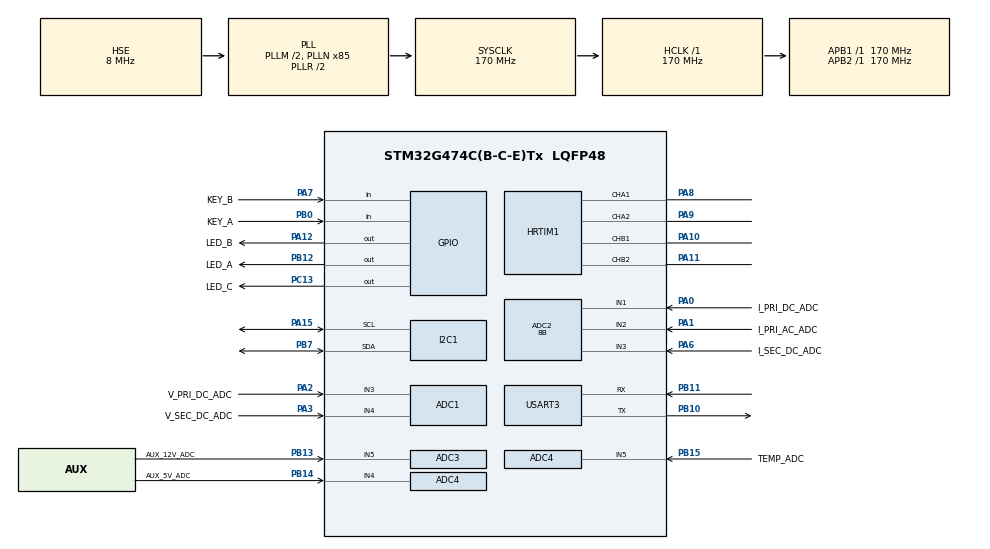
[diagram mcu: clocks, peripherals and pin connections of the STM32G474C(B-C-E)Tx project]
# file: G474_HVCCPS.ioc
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ADC1.Channel-0\#ChannelRegularConversion=ADC_CHANNEL_4
ADC1.Channel-1\#ChannelRegularConversion=ADC_CHANNEL_3
ADC1.DMAContinuousRequests=ENABLE
ADC1.EOCSelection=ADC_EOC_SEQ_CONV
ADC1.EnableInjectedConversion=DISABLE
ADC1.ExternalTrigConv=ADC_EXTERNALTRIG_HRTIM_TRG1
ADC1.NbrOfConversion=2
ADC1.NbrOfConversionFlag=1
ADC1.OffsetNumber-0\#ChannelRegularConversion=ADC_OFFSET_NONE
ADC1.OffsetNumber-1\#ChannelRegularConversion=ADC_OFFSET_NONE
ADC1.Overrun=ADC_OVR_DATA_OVERWRITTEN
ADC1.OversamplingMode=DISABLE
ADC1.Rank-0\#ChannelRegularConversion=1
ADC1.Rank-1\#ChannelRegularConversion=2
ADC1.Rank1_Channel=ADC_CHANNEL_3
ADC1.SamplingTime-0\#ChannelRegularConversion=ADC_SAMPLETIME_2CYCLES_5
ADC1.SamplingTime-1\#ChannelRegularConversion=ADC_SAMPLETIME_2CYCLES_5
ADC1.master=1
ADC2.Channel-12\#ChannelRegularConversion=ADC_CHANNEL_2
ADC2.Channel-14\#ChannelRegularConversion=ADC_CHANNEL_3
ADC2.Channel-15\#ChannelRegularConversion=ADC_CHANNEL_1
ADC2.ContinuousConvMode=DISABLE
ADC2.DMAContinuousRequests=ENABLE
ADC2.EOCSelection=ADC_EOC_SEQ_CONV
ADC2.EnableInjectedConversion=DISABLE
ADC2.EnableRegularConversion=ENABLE
ADC2.ExternalTrigConv=ADC_EXTERNALTRIG_HRTIM_TRG1
ADC2.NbrOfConversion=3
ADC2.NbrOfConversionFlag=1
ADC2.OffsetNumber-12\#ChannelRegularConversion=ADC_OFFSET_NONE
ADC2.OffsetNumber-14\#ChannelRegularConversion=ADC_OFFSET_NONE
ADC2.OffsetNumber-15\#ChannelRegularConversion=ADC_OFFSET_NONE
ADC2.Overrun=ADC_OVR_DATA_OVERWRITTEN
ADC2.Rank-12\#ChannelRegularConversion=1
ADC2.Rank-14\#ChannelRegularConversion=2
ADC2.Rank-15\#ChannelRegularConversion=3
ADC2.Resolution=ADC_RESOLUTION_8B
ADC2.SamplingTime-12\#ChannelRegularConversion=ADC_SAMPLETIME_2CYCLES_5
ADC2.SamplingTime-14\#ChannelRegularConversion=ADC_SAMPLETIME_2CYCLES_5
ADC2.SamplingTime-15\#ChannelRegularConversion=ADC_SAMPLETIME_2CYCLES_5
ADC3.Channel-1\#ChannelRegularConversion=ADC_CHANNEL_5
ADC3.ClockPrescaler=ADC_CLOCK_SYNC_PCLK_DIV4
ADC3.ContinuousConvMode=DISABLE
ADC3.DMAContinuousRequests=ENABLE
ADC3.EOCSelection=ADC_EOC_SEQ_CONV
ADC3.ExternalTrigConv=ADC_EXTERNALTRIG_HRTIM_TRG3
ADC3.NbrOfConversion=1
ADC3.NbrOfConversionFlag=1
ADC3.OffsetNumber-1\#ChannelRegularConversion=ADC_OFFSET_NONE
ADC3.Overrun=ADC_OVR_DATA_OVERWRITTEN
ADC3.OversamplingMode=DISABLE
ADC3.Rank-1\#ChannelRegularConversion=1
ADC3.SamplingTime-1\#ChannelRegularConversion=ADC_SAMPLETIME_6CYCLES_5
ADC3.master=1
ADC4.Channel-0\#ChannelRegularConversion=ADC_CHANNEL_4
ADC4.Channel-2\#ChannelRegularConversion=ADC_CHANNEL_5
ADC4.ContinuousConvMode=DISABLE
ADC4.DMAContinuousRequests=ENABLE
ADC4.EOCSelection=ADC_EOC_SEQ_CONV
ADC4.ExternalTrigConv=ADC_EXTERNALTRIG_HRTIM_TRG3
ADC4.NbrOfConversion=2
ADC4.NbrOfConversionFlag=1
ADC4.OffsetNumber-0\#ChannelRegularConversion=ADC_OFFSET_NONE
ADC4.OffsetNumber-2\#ChannelRegularConversion=ADC_OFFSET_NONE
ADC4.Overrun=ADC_OVR_DATA_OVERWRITTEN
ADC4.OversamplingMode=DISABLE
ADC4.Rank-0\#ChannelRegularConversion=1
ADC4.Rank-2\#ChannelRegularConversion=2
ADC4.SamplingTime-0\#ChannelRegularConversion=ADC_SAMPLETIME_6CYCLES_5
ADC4.SamplingTime-2\#ChannelRegularConversion=ADC_SAMPLETIME_6CYCLES_5
ADC5.Channel-0\#ChannelRegularConversion=ADC_CHANNEL_TEMPSENSOR_ADC5
ADC5.Channel-1\#ChannelRegularConversion=ADC_CHANNEL_VREFINT
ADC5.ContinuousConvMode=DISABLE
ADC5.DMAContinuousRequests=ENABLE
ADC5.EOCSelection=ADC_EOC_SEQ_CONV
ADC5.ExternalTrigConv=ADC_EXTERNALTRIG_HRTIM_TRG2
ADC5.NbrOfConversion=2
ADC5.NbrOfConversionFlag=1
ADC5.OffsetNumber-0\#ChannelRegularConversion=ADC_OFFSET_NONE
ADC5.OffsetNumber-1\#ChannelRegularConversion=ADC_OFFSET_NONE
ADC5.Overrun=ADC_OVR_DATA_OVERWRITTEN
ADC5.OversamplingMode=DISABLE
ADC5.Rank-0\#ChannelRegularConversion=1
ADC5.Rank-1\#ChannelRegularConversion=2
ADC5.SamplingTime-0\#ChannelRegularConversion=ADC_SAMPLETIME_247CYCLES_5
ADC5.SamplingTime-1\#ChannelRegularConversion=ADC_SAMPLETIME_247CYCLES_5
COMP1.TriggerMode=COMP_TRIGGERMODE_EVENT_RISING
DAC1.DAC_SampleAndHold-DAC_OUT1_Int=DAC_SAMPLEANDHOLD_DISABLE
Dma.ADC1.5.Direction=DMA_PERIPH_TO_MEMORY
Dma.ADC1.5.EventEnable=DISABLE
Dma.ADC1.5.Instance=DMA1_Channel1
Dma.ADC1.5.MemDataAlignment=DMA_MDATAALIGN_HALFWORD
Dma.ADC1.5.MemInc=DMA_MINC_ENABLE
Dma.ADC1.5.Mode=DMA_CIRCULAR
Dma.ADC1.5.PeriphDataAlignment=DMA_PDATAALIGN_HALFWORD
Dma.ADC1.5.PeriphInc=DMA_PINC_DISABLE
Dma.ADC1.5.Polarity=HAL_DMAMUX_REQ_GEN_RISING
Dma.ADC1.5.Priority=DMA_PRIORITY_HIGH
Dma.ADC1.5.RequestNumber=1
Dma.ADC1.5.SignalID=NONE
Dma.ADC1.5.SyncEnable=DISABLE
Dma.ADC1.5.SyncPolarity=HAL_DMAMUX_SYNC_NO_EVENT
Dma.ADC1.5.SyncRequestNumber=1
Dma.ADC1.5.SyncSignalID=NONE
Dma.ADC2.6.Direction=DMA_PERIPH_TO_MEMORY
Dma.ADC2.6.EventEnable=DISABLE
Dma.ADC2.6.Instance=DMA1_Channel2
Dma.ADC2.6.MemDataAlignment=DMA_MDATAALIGN_HALFWORD
Dma.ADC2.6.MemInc=DMA_MINC_ENABLE
Dma.ADC2.6.Mode=DMA_CIRCULAR
Dma.ADC2.6.PeriphDataAlignment=DMA_PDATAALIGN_HALFWORD
Dma.ADC2.6.PeriphInc=DMA_PINC_DISABLE
Dma.ADC2.6.Polarity=HAL_DMAMUX_REQ_GEN_RISING
Dma.ADC2.6.Priority=DMA_PRIORITY_HIGH
Dma.ADC2.6.RequestNumber=1
Dma.ADC2.6.SignalID=NONE
Dma.ADC2.6.SyncEnable=DISABLE
Dma.ADC2.6.SyncPolarity=HAL_DMAMUX_SYNC_NO_EVENT
Dma.ADC2.6.SyncRequestNumber=1
Dma.ADC2.6.SyncSignalID=NONE
Dma.ADC3.2.Direction=DMA_PERIPH_TO_MEMORY
Dma.ADC3.2.EventEnable=DISABLE
Dma.ADC3.2.Instance=DMA2_Channel1
Dma.ADC3.2.MemDataAlignment=DMA_MDATAALIGN_HALFWORD
Dma.ADC3.2.MemInc=DMA_MINC_ENABLE
Dma.ADC3.2.Mode=DMA_CIRCULAR
Dma.ADC3.2.PeriphDataAlignment=DMA_PDATAALIGN_HALFWORD
Dma.ADC3.2.PeriphInc=DMA_PINC_DISABLE
Dma.ADC3.2.Polarity=HAL_DMAMUX_REQ_GEN_RISING
Dma.ADC3.2.Priority=DMA_PRIORITY_HIGH
Dma.ADC3.2.RequestNumber=1
Dma.ADC3.2.SignalID=NONE
Dma.ADC3.2.SyncEnable=DISABLE
Dma.ADC3.2.SyncPolarity=HAL_DMAMUX_SYNC_NO_EVENT
Dma.ADC3.2.SyncRequestNumber=1
Dma.ADC3.2.SyncSignalID=NONE
Dma.ADC4.3.Direction=DMA_PERIPH_TO_MEMORY
Dma.ADC4.3.EventEnable=DISABLE
Dma.ADC4.3.Instance=DMA2_Channel2
Dma.ADC4.3.MemDataAlignment=DMA_MDATAALIGN_HALFWORD
Dma.ADC4.3.MemInc=DMA_MINC_ENABLE
Dma.ADC4.3.Mode=DMA_CIRCULAR
Dma.ADC4.3.PeriphDataAlignment=DMA_PDATAALIGN_HALFWORD
Dma.ADC4.3.PeriphInc=DMA_PINC_DISABLE
Dma.ADC4.3.Polarity=HAL_DMAMUX_REQ_GEN_RISING
Dma.ADC4.3.Priority=DMA_PRIORITY_HIGH
Dma.ADC4.3.RequestNumber=1
Dma.ADC4.3.SignalID=NONE
Dma.ADC4.3.SyncEnable=DISABLE
Dma.ADC4.3.SyncPolarity=HAL_DMAMUX_SYNC_NO_EVENT
Dma.ADC4.3.SyncRequestNumber=1
Dma.ADC4.3.SyncSignalID=NONE
Dma.ADC5.4.Direction=DMA_PERIPH_TO_MEMORY
Dma.ADC5.4.EventEnable=DISABLE
Dma.ADC5.4.Instance=DMA2_Channel3
Dma.ADC5.4.MemDataAlignment=DMA_MDATAALIGN_HALFWORD
Dma.ADC5.4.MemInc=DMA_MINC_ENABLE
Dma.ADC5.4.Mode=DMA_CIRCULAR
Dma.ADC5.4.PeriphDataAlignment=DMA_PDATAALIGN_HALFWORD
Dma.ADC5.4.PeriphInc=DMA_PINC_DISABLE
Dma.ADC5.4.Polarity=HAL_DMAMUX_REQ_GEN_RISING
Dma.ADC5.4.Priority=DMA_PRIORITY_HIGH
Dma.ADC5.4.RequestNumber=1
Dma.ADC5.4.SignalID=NONE
Dma.ADC5.4.SyncEnable=DISABLE
Dma.ADC5.4.SyncPolarity=HAL_DMAMUX_SYNC_NO_EVENT
Dma.ADC5.4.SyncRequestNumber=1
Dma.ADC5.4.SyncSignalID=NONE
Dma.I2C1_RX.7.Direction=DMA_PERIPH_TO_MEMORY
Dma.I2C1_RX.7.EventEnable=DISABLE
Dma.I2C1_RX.7.Instance=DMA2_Channel6
Dma.I2C1_RX.7.MemDataAlignment=DMA_MDATAALIGN_BYTE
Dma.I2C1_RX.7.MemInc=DMA_MINC_ENABLE
Dma.I2C1_RX.7.Mode=DMA_NORMAL
Dma.I2C1_RX.7.PeriphDataAlignment=DMA_PDATAALIGN_BYTE
Dma.I2C1_RX.7.PeriphInc=DMA_PINC_DISABLE
Dma.I2C1_RX.7.Polarity=HAL_DMAMUX_REQ_GEN_RISING
Dma.I2C1_RX.7.Priority=DMA_PRIORITY_MEDIUM
Dma.I2C1_RX.7.RequestNumber=1
Dma.I2C1_RX.7.SignalID=NONE
Dma.I2C1_RX.7.SyncEnable=DISABLE
Dma.I2C1_RX.7.SyncPolarity=HAL_DMAMUX_SYNC_NO_EVENT
Dma.I2C1_RX.7.SyncRequestNumber=1
Dma.I2C1_RX.7.SyncSignalID=NONE
Dma.I2C1_TX.8.Direction=DMA_MEMORY_TO_PERIPH
Dma.I2C1_TX.8.EventEnable=DISABLE
Dma.I2C1_TX.8.Instance=DMA2_Channel7
Dma.I2C1_TX.8.MemDataAlignment=DMA_MDATAALIGN_BYTE
Dma.I2C1_TX.8.MemInc=DMA_MINC_ENABLE
Dma.I2C1_TX.8.Mode=DMA_NORMAL
Dma.I2C1_TX.8.PeriphDataAlignment=DMA_PDATAALIGN_BYTE
Dma.I2C1_TX.8.PeriphInc=DMA_PINC_DISABLE
Dma.I2C1_TX.8.Polarity=HAL_DMAMUX_REQ_GEN_RISING
Dma.I2C1_TX.8.Priority=DMA_PRIORITY_MEDIUM
Dma.I2C1_TX.8.RequestNumber=1
Dma.I2C1_TX.8.SignalID=NONE
Dma.I2C1_TX.8.SyncEnable=DISABLE
Dma.I2C1_TX.8.SyncPolarity=HAL_DMAMUX_SYNC_NO_EVENT
Dma.I2C1_TX.8.SyncRequestNumber=1
Dma.I2C1_TX.8.SyncSignalID=NONE
Dma.Request0=USART3_RX
Dma.Request1=USART3_TX
Dma.Request2=ADC3
Dma.Request3=ADC4
Dma.Request4=ADC5
Dma.Request5=ADC1
Dma.Request6=ADC2
Dma.Request7=I2C1_RX
Dma.Request8=I2C1_TX
Dma.USART3_RX.0.Direction=DMA_PERIPH_TO_MEMORY
Dma.USART3_RX.0.EventEnable=DISABLE
Dma.USART3_RX.0.Instance=DMA2_Channel5
Dma.USART3_RX.0.MemDataAlignment=DMA_MDATAALIGN_BYTE
Dma.USART3_RX.0.MemInc=DMA_MINC_ENABLE
Dma.USART3_RX.0.Mode=DMA_NORMAL
Dma.USART3_RX.0.PeriphDataAlignment=DMA_PDATAALIGN_BYTE
Dma.USART3_RX.0.PeriphInc=DMA_PINC_DISABLE
Dma.USART3_RX.0.Polarity=HAL_DMAMUX_REQ_GEN_RISING
Dma.USART3_RX.0.Priority=DMA_PRIORITY_MEDIUM
Dma.USART3_RX.0.RequestNumber=1
Dma.USART3_RX.0.SignalID=NONE
Dma.USART3_RX.0.SyncEnable=DISABLE
Dma.USART3_RX.0.SyncPolarity=HAL_DMAMUX_SYNC_NO_EVENT
Dma.USART3_RX.0.SyncRequestNumber=1
Dma.USART3_RX.0.SyncSignalID=NONE
Dma.USART3_TX.1.Direction=DMA_MEMORY_TO_PERIPH
Dma.USART3_TX.1.EventEnable=DISABLE
Dma.USART3_TX.1.Instance=DMA2_Channel4
Dma.USART3_TX.1.MemDataAlignment=DMA_MDATAALIGN_BYTE
Dma.USART3_TX.1.MemInc=DMA_MINC_ENABLE
Dma.USART3_TX.1.Mode=DMA_NORMAL
Dma.USART3_TX.1.PeriphDataAlignment=DMA_PDATAALIGN_BYTE
Dma.USART3_TX.1.PeriphInc=DMA_PINC_DISABLE
Dma.USART3_TX.1.Polarity=HAL_DMAMUX_REQ_GEN_RISING
Dma.USART3_TX.1.Priority=DMA_PRIORITY_MEDIUM
Dma.USART3_TX.1.RequestNumber=1
Dma.USART3_TX.1.SignalID=NONE
Dma.USART3_TX.1.SyncEnable=DISABLE
Dma.USART3_TX.1.SyncPolarity=HAL_DMAMUX_SYNC_NO_EVENT
Dma.USART3_TX.1.SyncRequestNumber=1
Dma.USART3_TX.1.SyncSignalID=NONE
HRTIM1.ADCTrigger1_Source1=HRTIM_ADCTRIGGEREVENT13_MASTER_CMP1
HRTIM1.ADCTrigger1_Source2=HRTIM_ADCTRIGGEREVENT13_TIMERC_PERIOD
HRTIM1.ADCTrigger2_Source1=HRTIM_ADCTRIGGEREVENT24_MASTER_CMP1
HRTIM1.ADCTrigger2_Source2=HRTIM_ADCTRIGGEREVENT24_TIMERD_PERIOD
HRTIM1.ADCTrigger3_Source1=HRTIM_ADCTRIGGEREVENT13_MASTER_CMP1
HRTIM1.ADCTrigger3_Source2=HRTIM_ADCTRIGGEREVENT13_TIMERE_PERIOD
HRTIM1.ADCTrigger_Id1=HRTIM_ADCTRIGGER_1
HRTIM1.ADCTrigger_Id2=HRTIM_ADCTRIGGER_2
HRTIM1.ADCTrigger_Id3=HRTIM_ADCTRIGGER_3
HRTIM1.ADCTrigger_Id4=__NULL
HRTIM1.BlankingSourceFaultLine4=__NULL
HRTIM1.BurstDMAconfig-MasterTimer=__NULL
HRTIM1.BurstMode-MasterTimer=HRTIM_TIMERBURSTMODE_RESETCOUNTER
HRTIM1.BurstMode-Output_TA1TA2=HRTIM_TIMERBURSTMODE_RESETCOUNTER
HRTIM1.BurstMode-Output_TB1TB2=HRTIM_TIMERBURSTMODE_RESETCOUNTER
HRTIM1.CaptureUnit1-No_output_TC=__NULL
HRTIM1.CompareUnit1-MasterTimer=HRTIM_COMPAREUNIT_1
HRTIM1.CompareUnit1-Output_TA1TA2=HRTIM_COMPAREUNIT_1
HRTIM1.CompareUnit1-Output_TB1TB2=HRTIM_COMPAREUNIT_1
HRTIM1.CompareUnit2-MasterTimer=__NULL
HRTIM1.CompareUnit2-Output_TA1TA2=__NULL
HRTIM1.CompareUnit3-MasterTimer=HRTIM_COMPAREUNIT_3
HRTIM1.CompareUnit3-Output_TA1TA2=__NULL
HRTIM1.CompareUnit4-MasterTimer=__NULL
HRTIM1.CompareUnit4-Output_TA1TA2=__NULL
HRTIM1.CompareValue1-MasterTimer=48
HRTIM1.CompareValue1-Output_TA1TA2=HRTIM_PRD/2
HRTIM1.CompareValue1-Output_TB1TB2=HRTIM_PRD/2
HRTIM1.CompareValue3-MasterTimer=48
HRTIM1.DeadTimeInsertion-Output_TA1TA2=HRTIM_TIMDEADTIMEINSERTION_ENABLED
HRTIM1.DeadTimeInsertion-Output_TB1TB2=HRTIM_TIMDEADTIMEINSERTION_ENABLED
HRTIM1.Event_EEV1=__NULL
HRTIM1.Event_EEV2=__NULL
HRTIM1.Event_EEV3=__NULL
HRTIM1.Event_EEV4=__NULL
HRTIM1.Event_EEV5=__NULL
HRTIM1.Event_EEV6=__NULL
HRTIM1.Event_EEV7=__NULL
HRTIM1.Event_EEV8=__NULL
HRTIM1.FallingValue-Output_TA1TA2=DEAD_TIME
HRTIM1.FallingValue-Output_TB1TB2=DEAD_TIME
HRTIM1.FaultEnable_Source1-Output_TA1TA2=HRTIM_TIMFAULTENABLE_FAULT4
HRTIM1.FaultEnable_Source1-Output_TB1TB2=HRTIM_TIMFAULTENABLE_FAULT4
HRTIM1.FaultLevel1-Output_TA1TA2=HRTIM_OUTPUTFAULTLEVEL_INACTIVE
HRTIM1.FaultLevel1-Output_TB1TB2=HRTIM_OUTPUTFAULTLEVEL_INACTIVE
HRTIM1.FaultLevel2-Output_TA1TA2=HRTIM_OUTPUTFAULTLEVEL_INACTIVE
HRTIM1.FaultLevel2-Output_TB1TB2=HRTIM_OUTPUTFAULTLEVEL_INACTIVE
HRTIM1.Fault_Line1=__NULL
HRTIM1.Fault_Line3=__NULL
HRTIM1.Fault_Line4=HRTIM_FAULT_4
HRTIM1.Filter_FaultLine4=HRTIM_FAULTFILTER_7
HRTIM1.InterruptRequests1_Master=HRTIM_MASTER_IT_MREP
HRTIM1.ModeTimeBase-Output_TA1TA2=HRTIM_MODE_SINGLESHOT_RETRIGGERABLE
HRTIM1.ModeTimeBase-Output_TB1TB2=HRTIM_MODE_SINGLESHOT_RETRIGGERABLE
HRTIM1.NumberADCTriggerSource1=2
HRTIM1.NumberADCTriggerSource2=2
HRTIM1.NumberADCTriggerSource3=2
HRTIM1.NumberFaultEnable-No_output_TC=0
HRTIM1.NumberFaultEnable-Output_TA1TA2=1
HRTIM1.NumberFaultEnable-Output_TB1TB2=1
HRTIM1.NumberInterruptRequests_Master-MasterTimer=1
HRTIM1.NumberResetSource1-Output_TA1TA2=1
HRTIM1.NumberResetSource1-Output_TB1TB2=1
HRTIM1.NumberResetTrigger-No_output_TC=1
HRTIM1.NumberResetTrigger-No_output_TD=1
HRTIM1.NumberResetTrigger-No_output_TE=1
HRTIM1.NumberResetTrigger-Output_TA1TA2=1
HRTIM1.NumberResetTrigger-Output_TB1TB2=1
HRTIM1.NumberSetSource1-Output_TA1TA2=1
HRTIM1.NumberSetSource1-Output_TB1TB2=1
HRTIM1.NumberUpdateTrigger-No_output_TC=1
HRTIM1.NumberUpdateTrigger-No_output_TD=1
HRTIM1.NumberUpdateTrigger-No_output_TE=1
HRTIM1.NumberUpdateTrigger-Output_TA1TA2=1
HRTIM1.NumberUpdateTrigger-Output_TB1TB2=1
HRTIM1.Periode_MASTER=HRTIM_PRD
HRTIM1.Periode_TA=HRTIM_PRD
HRTIM1.Periode_TB=HRTIM_PRD
HRTIM1.Periode_TC=HRTIM_PRD/3+1
HRTIM1.Periode_TD=HRTIM_PRD*8/10+1
HRTIM1.Periode_TE=HRTIM_PRD/2+1
HRTIM1.Polarity2-Output_TB1TB2=HRTIM_OUTPUTPOLARITY_HIGH
HRTIM1.PreloadEnable-MasterTimer=HRTIM_PRELOAD_ENABLED
HRTIM1.PreloadEnable-No_output_TC=HRTIM_PRELOAD_ENABLED
HRTIM1.PreloadEnable-No_output_TD=HRTIM_PRELOAD_ENABLED
HRTIM1.PreloadEnable-No_output_TE=HRTIM_PRELOAD_ENABLED
HRTIM1.PreloadEnable-Output_TA1TA2=HRTIM_PRELOAD_ENABLED
HRTIM1.PreloadEnable-Output_TB1TB2=HRTIM_PRELOAD_ENABLED
HRTIM1.PrescalerDead-Output_TA1TA2=HRTIM_TIMDEADTIME_PRESCALERRATIO_DIV1
HRTIM1.PrescalerDead-Output_TB1TB2=HRTIM_TIMDEADTIME_PRESCALERRATIO_DIV1
HRTIM1.PrescalerRatio_MASTER=HRTIM_PRESCALERRATIO_MUL4
HRTIM1.PrescalerRatio_TA=HRTIM_PRESCALERRATIO_MUL4
HRTIM1.PrescalerRatio_TB=HRTIM_PRESCALERRATIO_MUL4
HRTIM1.PrescalerRatio_TC=HRTIM_PRESCALERRATIO_MUL32
HRTIM1.PrescalerRatio_TD=HRTIM_PRESCALERRATIO_MUL32
HRTIM1.RepetitionUpdate-MasterTimer=HRTIM_UPDATEONREPETITION_ENABLED
HRTIM1.RepetitionUpdate-No_output_TC=HRTIM_UPDATEONREPETITION_DISABLED
HRTIM1.RepetitionUpdate-No_output_TD=HRTIM_UPDATEONREPETITION_DISABLED
HRTIM1.RepetitionUpdate-Output_TA1TA2=HRTIM_UPDATEONREPETITION_DISABLED
HRTIM1.RepetitionUpdate-Output_TB1TB2=HRTIM_UPDATEONREPETITION_DISABLED
HRTIM1.ResetModeFaultLine4=HRTIM_FAULTCOUNTERRST_UNCONDITIONAL
HRTIM1.ResetOutput1_Source1-Output_TA1TA2=HRTIM_OUTPUTRESET_TIMCMP1
HRTIM1.ResetOutput1_Source1-Output_TB1TB2=HRTIM_OUTPUTRESET_TIMCMP1
HRTIM1.ResetTrigger1-No_output_TC=HRTIM_TIMRESETTRIGGER_MASTER_CMP1
HRTIM1.ResetTrigger1-No_output_TD=HRTIM_TIMRESETTRIGGER_MASTER_CMP1
HRTIM1.ResetTrigger1-No_output_TE=HRTIM_TIMRESETTRIGGER_MASTER_CMP1
HRTIM1.ResetTrigger1-Output_TA1TA2=HRTIM_TIMRESETTRIGGER_MASTER_CMP1
HRTIM1.ResetTrigger1-Output_TB1TB2=HRTIM_TIMRESETTRIGGER_MASTER_CMP3
HRTIM1.ResetUpdate-Output_TA1TA2=HRTIM_TIMUPDATEONRESET_DISABLED
HRTIM1.ResetUpdate-Output_TB1TB2=HRTIM_TIMUPDATEONRESET_DISABLED
HRTIM1.RisingValue-Output_TA1TA2=DEAD_TIME
HRTIM1.RisingValue-Output_TB1TB2=DEAD_TIME
HRTIM1.SetOutput1_Source1-Output_TA1TA2=HRTIM_OUTPUTSET_MASTERCMP1
HRTIM1.SetOutput1_Source1-Output_TB1TB2=HRTIM_OUTPUTSET_MASTERCMP3
HRTIM1.Source_FaultLine4=HRTIM_FAULTSOURCE_INTERNAL
HRTIM1.UpdateTrigger1-No_output_TC=HRTIM_TIMUPDATETRIGGER_MASTER
HRTIM1.UpdateTrigger1-No_output_TD=HRTIM_TIMUPDATETRIGGER_MASTER
HRTIM1.UpdateTrigger1-No_output_TE=HRTIM_TIMUPDATETRIGGER_MASTER
HRTIM1.UpdateTrigger1-Output_TA1TA2=HRTIM_TIMUPDATETRIGGER_MASTER
HRTIM1.UpdateTrigger1-Output_TB1TB2=HRTIM_TIMUPDATETRIGGER_MASTER
HRTIM1.postscaler2=10
I2C1.Timing=0x40B285C2
IWDG.Prescaler=IWDG_PRESCALER_64
IWDG.Reload=99
IWDG.Window=4095
Mcu.Family=STM32G4
Mcu.Name=STM32G474C(B-C-E)Tx
Mcu.Package=LQFP48
Mcu.UserConstants=HRTIM_PRD,15111;DEAD_TIME,34
NVIC.DMA2_Channel4_IRQn=true\:1\:0\:true\:false\:true\:false\:true\:true
NVIC.DMA2_Channel5_IRQn=true\:1\:0\:true\:false\:true\:false\:true\:true
NVIC.DMA2_Channel6_IRQn=true\:1\:0\:true\:false\:true\:false\:true\:true
NVIC.DMA2_Channel7_IRQn=true\:1\:0\:true\:false\:true\:false\:true\:true
NVIC.HRTIM1_Master_IRQn=true\:0\:0\:false\:false\:true\:true\:true\:true
NVIC.PriorityGroup=NVIC_PRIORITYGROUP_2
NVIC.TIM6_DAC_IRQn=true\:3\:0\:true\:false\:true\:true\:true\:true
NVIC.TIM7_DAC_IRQn=true\:2\:0\:true\:false\:true\:true\:true\:true
NVIC.USART3_IRQn=true\:0\:1\:true\:false\:true\:true\:true\:true
PA0.GPIO_Label=I_PRI_DC_ADC
PA0.Mode=IN1-Single-Ended
PA0.Signal=ADC2_IN1
PA1.GPIO_Label=I_PRI_AC_ADC
PA1.Signal=SharedAnalog_PA1
PA10.GPIO_Mode=GPIO_MODE_AF_PP
PA10.GPIO_PuPd=GPIO_NOPULL
PA10.GPIO_Speed_High_Default=GPIO_SPEED_FREQ_VERY_HIGH
PA10.Mode=Output_TB1TB2
PA10.Signal=HRTIM1_CHB1
PA11.GPIO_Mode=GPIO_MODE_AF_PP
PA11.GPIO_PuPd=GPIO_NOPULL
PA11.GPIO_Speed_High_Default=GPIO_SPEED_FREQ_VERY_HIGH
PA11.Mode=Output_TB1TB2
PA11.Signal=HRTIM1_CHB2
PA12.GPIO_Label=LED_B
PA12.Signal=GPIO_Output
PA15.Mode=I2C
PA15.Signal=I2C1_SCL
PA2.GPIO_Label=V_PRI_DC_ADC
PA2.Mode=IN3-Single-Ended
PA2.Signal=ADC1_IN3
PA3.GPIO_Label=V_SEC_DC_ADC
PA3.Mode=IN4-Single-Ended
PA3.Signal=ADC1_IN4
PA6.GPIO_Label=I_SEC_DC_ADC
PA6.Mode=IN3-Single-Ended
PA6.Signal=ADC2_IN3
PA7.GPIO_Label=KEY_B
PA7.GPIO_PuPd=GPIO_PULLUP
PA7.Signal=GPIO_Input
PA8.GPIO_Mode=GPIO_MODE_AF_PP
PA8.GPIO_PuPd=GPIO_NOPULL
PA8.GPIO_Speed_High_Default=GPIO_SPEED_FREQ_VERY_HIGH
PA8.Mode=Output_TA1TA2
PA8.Signal=HRTIM1_CHA1
PA9.GPIO_Mode=GPIO_MODE_AF_PP
PA9.GPIO_PuPd=GPIO_NOPULL
PA9.GPIO_Speed_High_Default=GPIO_SPEED_FREQ_VERY_HIGH
PA9.Mode=Output_TA1TA2
PA9.Signal=HRTIM1_CHA2
PB0.GPIO_Label=KEY_A
PB0.GPIO_PuPd=GPIO_PULLUP
PB0.Signal=GPIO_Input
PB10.Mode=Asynchronous
PB10.Signal=USART3_TX
PB11.Mode=Asynchronous
PB11.Signal=USART3_RX
PB12.GPIO_Label=LED_A
PB12.Signal=GPIO_Output
PB13.GPIO_Label=AUX_12V_ADC
PB13.Mode=IN5-Single-Ended
PB13.Signal=ADC3_IN5
PB14.GPIO_Label=AUX_5V_ADC
PB14.Mode=IN4-Single-Ended
PB14.Signal=ADC4_IN4
PB15.GPIO_Label=TEMP_ADC
PB15.Mode=IN5-Single-Ended
PB15.Signal=ADC4_IN5
PB7.Mode=I2C
PB7.Signal=I2C1_SDA
PC13.GPIO_Label=LED_C
PC13.PinState=GPIO_PIN_RESET
PC13.Signal=GPIO_Output
PF0-OSC_IN.Mode=HSE-External-Oscillator
PF0-OSC_IN.Signal=RCC_OSC_IN
PF1-OSC_OUT.Mode=HSE-External-Oscillator
PF1-OSC_OUT.Signal=RCC_OSC_OUT
ProjectManager.HeapSize=0x200
ProjectManager.StackSize=0x400
ProjectManager.TargetToolchain=MDK-ARM V5.32
RCC.ADC12Freq_Value=170000000
RCC.ADC345Freq_Value=170000000
RCC.AHBFreq_Value=170000000
RCC.APB1Freq_Value=170000000
RCC.APB1TimFreq_Value=170000000
RCC.APB2Freq_Value=170000000
RCC.APB2TimFreq_Value=170000000
RCC.CortexFreq_Value=170000000
RCC.EXTERNAL_CLOCK_VALUE=12288000
RCC.HCLKFreq_Value=170000000
RCC.HSE_VALUE=8000000
RCC.HSI48_VALUE=48000000
RCC.HSI_VALUE=16000000
RCC.LSE_VALUE=32768
RCC.PLLM=RCC_PLLM_DIV2
RCC.PLLN=85
RCC.PLLSourceVirtual=RCC_PLLSOURCE_HSE
RCC.SYSCLKFreq_VALUE=170000000
RCC.SYSCLKSource=RCC_SYSCLKSOURCE_PLLCLK
RCC.USBFreq_Value=170000000
RCC.VCOOutputFreq_Value=340000000
SH.SharedAnalog_PA1.0=ADC2_IN2,IN2-Single-Ended
SH.SharedAnalog_PA1.1=COMP1_INP,INP
TIM6.AutoReloadPreload=TIM_AUTORELOAD_PRELOAD_DISABLE
TIM6.Dithering=Disable
TIM6.PeriodNoDither=99
TIM6.Prescaler=16999
TIM6.TIM_MasterOutputTrigger=TIM_TRGO_UPDATE
TIM7.AutoReloadPreload=TIM_AUTORELOAD_PRELOAD_DISABLE
TIM7.PeriodNoDither=99
TIM7.Prescaler=16999
TIM7.TIM_MasterOutputTrigger=TIM_TRGO_UPDATE
USART3.VirtualMode-Asynchronous=VM_ASYNC
VP_ADC5_TempSens_Input.Mode=IN-TempSens
VP_ADC5_Vref_Input.Mode=IN-Vrefint
VP_COMP1_VS_DAC1OUT1.Mode=INM_DAC1OUT1
VP_DAC1_VS_DACI1.Mode=DAC_OUT1_Int
VP_HRTIM1_VS_hrtimMasterTimerNoOutput.Mode=MasterTimer
VP_HRTIM1_VS_hrtimTimerCNoOutput.Mode=No_output_TC
VP_HRTIM1_VS_hrtimTimerDNoOutput.Mode=No_output_TD
VP_HRTIM1_VS_hrtimTimerENoOutput.Mode=No_output_TE
VP_IWDG_VS_IWDG.Mode=IWDG_Activate
VP_SYS_VS_DBSignals.Mode=DisableDeadBatterySignals
VP_TIM6_VS_ClockSourceINT.Mode=Enable_Timer
VP_TIM7_VS_ClockSourceINT.Mode=Enable_Timer
board=custom

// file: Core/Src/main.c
/* USER CODE BEGIN Header */
/**
  ******************************************************************************
  * @file           : main.c
  * @brief          : Main program body
  ******************************************************************************
  * @attention
  *
  * Copyright (c) 2026 STMicroelectronics.
  * All rights reserved.
  *
  * This software is licensed under terms that can be found in the LICENSE file
  * in the root directory of this software component.
  * If no LICENSE file comes with this software, it is provided AS-IS.
  *
  ******************************************************************************
  */
/* USER CODE END Header */
#include "main.h"
#include "adc.h"
#include "comp.h"
#include "dac.h"
#include "dma.h"
#include "hrtim.h"
#include "i2c.h"
#include "iwdg.h"
#include "tim.h"
#include "usart.h"
#include "gpio.h"

/* USER CODE BEGIN Includes */
#include "app_core.h"

/* USER CODE END Includes */

void SystemClock_Config(void);

int main(void)
{

  /* MCU Configuration--------------------------------------------------------*/

  /* Reset of all peripherals, Initializes the Flash interface and the Systick. */
  HAL_Init();

  /* Configure the system clock */
  SystemClock_Config();

  /* Initialize all configured peripherals */
  MX_GPIO_Init();
  MX_DMA_Init();
  MX_USART3_UART_Init();
  MX_ADC3_Init();
  MX_ADC4_Init();
  MX_HRTIM1_Init();
  MX_ADC1_Init();
  MX_ADC2_Init();
  MX_ADC5_Init();
  MX_I2C1_Init();
  MX_COMP1_Init();
  MX_DAC1_Init();
  MX_IWDG_Init();
  MX_TIM6_Init();
  MX_TIM7_Init();
  /* USER CODE BEGIN 2 */
  APP_Init();

  /* USER CODE END 2 */

  /* Infinite loop */
  while (1)
  {

    /* USER CODE BEGIN 3 */
    APP_Task();
  }
  /* USER CODE END 3 */
}

void SystemClock_Config(void)
{
  RCC_OscInitTypeDef RCC_OscInitStruct = {0};
  RCC_ClkInitTypeDef RCC_ClkInitStruct = {0};

  /** Configure the main internal regulator output voltage
  */
  HAL_PWREx_ControlVoltageScaling(PWR_REGULATOR_VOLTAGE_SCALE1_BOOST);

  /** Initializes the RCC Oscillators according to the specified parameters
  * in the RCC_OscInitTypeDef structure.
  */
  RCC_OscInitStruct.OscillatorType = RCC_OSCILLATORTYPE_LSI|RCC_OSCILLATORTYPE_HSE;
  RCC_OscInitStruct.HSEState = RCC_HSE_ON;
  RCC_OscInitStruct.LSIState = RCC_LSI_ON;
  RCC_OscInitStruct.PLL.PLLState = RCC_PLL_ON;
  RCC_OscInitStruct.PLL.PLLSource = RCC_PLLSOURCE_HSE;
  RCC_OscInitStruct.PLL.PLLM = RCC_PLLM_DIV2;
  RCC_OscInitStruct.PLL.PLLN = 85;
  RCC_OscInitStruct.PLL.PLLP = RCC_PLLP_DIV2;
  RCC_OscInitStruct.PLL.PLLQ = RCC_PLLQ_DIV2;
  RCC_OscInitStruct.PLL.PLLR = RCC_PLLR_DIV2;
  if (HAL_RCC_OscConfig(&RCC_OscInitStruct) != HAL_OK)
  {
    Error_Handler();
  }

  /** Initializes the CPU, AHB and APB buses clocks
  */
  RCC_ClkInitStruct.ClockType = RCC_CLOCKTYPE_HCLK|RCC_CLOCKTYPE_SYSCLK
                              |RCC_CLOCKTYPE_PCLK1|RCC_CLOCKTYPE_PCLK2;
  RCC_ClkInitStruct.SYSCLKSource = RCC_SYSCLKSOURCE_PLLCLK;
  RCC_ClkInitStruct.AHBCLKDivider = RCC_SYSCLK_DIV1;
  RCC_ClkInitStruct.APB1CLKDivider = RCC_HCLK_DIV1;
  RCC_ClkInitStruct.APB2CLKDivider = RCC_HCLK_DIV1;

  if (HAL_RCC_ClockConfig(&RCC_ClkInitStruct, FLASH_LATENCY_4) != HAL_OK)
  {
    Error_Handler();
  }
}

void Error_Handler(void)
{
  __disable_irq();
  while (1)
  {
  }
}
